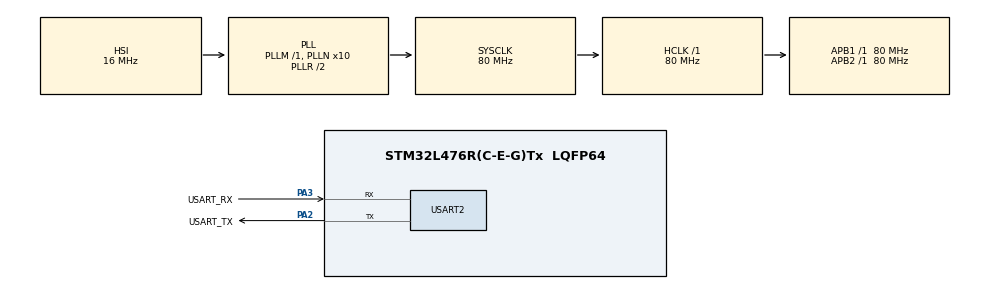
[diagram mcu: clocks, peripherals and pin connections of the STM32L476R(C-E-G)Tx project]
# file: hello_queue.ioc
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Mcu.Family=STM32L4
RCC.MSI_VALUE=4000000
RCC.PLLSourceVirtual=RCC_PLLSOURCE_HSI
PA14\ (JTCK-SWCLK).Mode=Serial_Wire
PA2.GPIO_PuPd=GPIO_NOPULL
VP_SYS_VS_tim6.Mode=TIM6
RCC.CortexFreq_Value=80000000
FREERTOS.Tasks01=sender0Task,16,128,StartSenderTask,Default,NULL,Dynamic,NULL,NULL;sender1Task,16,128,StartSenderTask,Default,NULL,Dynamic,NULL,NULL;receiver0Task,24,128,StartReceiverTask,Default,NULL,Dynamic,NULL,NULL
NVIC.TIM6_DAC_IRQn=true\:0\:0\:false\:false\:true\:false\:false\:true
PH0-OSC_IN\ (PH0).Signal=RCC_OSC_IN
PA3.GPIO_PuPd=GPIO_NOPULL
PA2.GPIO_Speed=GPIO_SPEED_FREQ_VERY_HIGH
PC15-OSC32_OUT\ (PC15).Signal=RCC_OSC32_OUT
PB3\ (JTDO-TRACESWO).GPIO_Label=SWO
PA14\ (JTCK-SWCLK).GPIO_Label=TCK
PC15-OSC32_OUT\ (PC15).Mode=LSE-External-Oscillator
PA3.GPIO_Speed=GPIO_SPEED_FREQ_VERY_HIGH
PH1-OSC_OUT\ (PH1).Signal=RCC_OSC_OUT
RCC.SYSCLKSource=RCC_SYSCLKSOURCE_PLLCLK
ProjectManager.StackSize=0x400
PB3\ (JTDO-TRACESWO).Signal=SYS_JTDO-SWO
PC14-OSC32_IN\ (PC14).Mode=LSE-External-Oscillator
VP_FREERTOS_VS_CMSIS_V2.Mode=CMSIS_V2
PA14\ (JTCK-SWCLK).Signal=SYS_JTCK-SWCLK
PA3.Mode=Asynchronous
ProjectManager.TargetToolchain=STM32CubeIDE
PA3.GPIO_Mode=GPIO_MODE_AF_PP
RCC.HCLKFreq_Value=80000000
RCC.APB2TimFreq_Value=80000000
RCC.USBFreq_Value=64000000
RCC.AHBFreq_Value=80000000
RCC.PREFETCH_ENABLE=1
RCC.HSE_VALUE=8000000
board=NUCLEO-L476RG
USART2.VirtualMode-Asynchronous=VM_ASYNC
RCC.VCOOutputFreq_Value=160000000
RCC.APB2Freq_Value=80000000
PA13\ (JTMS-SWDIO).GPIO_Label=TMS
RCC.ADCFreq_Value=64000000
Mcu.Name=STM32L476R(C-E-G)Tx
PA2.Signal=USART2_TX
PA13\ (JTMS-SWDIO).Mode=Serial_Wire
RCC.SYSCLKFreq_VALUE=80000000
Mcu.Package=LQFP64
NVIC.TimeBase=TIM6_DAC_IRQn
PC14-OSC32_IN\ (PC14).Signal=RCC_OSC32_IN
PA2.GPIO_Label=USART_TX
NVIC.TimeBaseIP=TIM6
ProjectManager.HeapSize=0x200
RCC.HSI_VALUE=16000000
NVIC.PriorityGroup=NVIC_PRIORITYGROUP_4
RCC.PLLN=10
RCC.APB1TimFreq_Value=80000000
PA2.Mode=Asynchronous
PA13\ (JTMS-SWDIO).Signal=SYS_JTMS-SWDIO
RCC.APB1Freq_Value=80000000
PA3.GPIO_Label=USART_RX
PA3.Signal=USART2_RX
PA2.GPIO_Mode=GPIO_MODE_AF_PP

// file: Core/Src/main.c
/* USER CODE BEGIN Header */
/**
  ******************************************************************************
  * @file           : main.c
  * @brief          : Main program body
  ******************************************************************************
  * @attention
  *
  * <h2><center>&copy; Copyright (c) 2021 STMicroelectronics.
  * All rights reserved.</center></h2>
  *
  * This software component is licensed by ST under BSD 3-Clause license,
  * the "License"; You may not use this file except in compliance with the
  * License. You may obtain a copy of the License at:
  *                        opensource.org/licenses/BSD-3-Clause
  *
  ******************************************************************************
  */
/* USER CODE END Header */
#include "main.h"
#include "cmsis_os.h"

/* USER CODE BEGIN Includes */
#include <stdio.h>
/* USER CODE END Includes */

/* USER CODE BEGIN PTD */
#ifdef __GNUC__
	#define PUTCHAR_PROTOTYPE int __io_putchar(int ch)
#else
	#define PUTCHAR_PROTOTYPE int fputc(int ch, FILE *f)
#endif /* __GNUC__ */
/* USER CODE END PTD */

UART_HandleTypeDef huart2;

/* Definitions for sender0Task */
osThreadId_t sender0TaskHandle;
const osThreadAttr_t sender0Task_attributes = {
  .name = "sender0Task",
  .stack_size = 128 * 4,
  .priority = (osPriority_t) osPriorityBelowNormal,
};
/* Definitions for sender1Task */
osThreadId_t sender1TaskHandle;
const osThreadAttr_t sender1Task_attributes = {
  .name = "sender1Task",
  .stack_size = 128 * 4,
  .priority = (osPriority_t) osPriorityBelowNormal,
};
/* Definitions for receiver0Task */
osThreadId_t receiver0TaskHandle;
const osThreadAttr_t receiver0Task_attributes = {
  .name = "receiver0Task",
  .stack_size = 128 * 4,
  .priority = (osPriority_t) osPriorityNormal,
};
/* USER CODE BEGIN PV */

typedef struct {
  uint8_t Buf[32];
  uint8_t Idx;
} MSGQUEUE_OBJ_t;

osMessageQueueId_t messageQueue;

/* USER CODE END PV */

void SystemClock_Config(void);
static void MX_GPIO_Init(void);
static void MX_USART2_UART_Init(void);
void StartSenderTask(void *argument);
void StartReceiverTask(void *argument);

int main(void)
{
  /* USER CODE BEGIN 1 */
	const char* sender0Tag = "Sender0";
	const char* sender1Tag = "Sender1";
	const char* sender2Tag = "Sender2";
  /* USER CODE END 1 */

  /* MCU Configuration--------------------------------------------------------*/

  /* Reset of all peripherals, Initializes the Flash interface and the Systick. */
  HAL_Init();

  /* Configure the system clock */
  SystemClock_Config();

  /* Initialize all configured peripherals */
  MX_GPIO_Init();
  MX_USART2_UART_Init();

  /* Init scheduler */
  osKernelInitialize();

  /* USER CODE BEGIN RTOS_QUEUES */
  /* add queues, ... */
  messageQueue = osMessageQueueNew(32, sizeof(MSGQUEUE_OBJ_t), NULL);
  if (messageQueue == NULL)
  {
  	printf("ERROR: messageQueue could not be created.\r\n");
  }
  /* USER CODE END RTOS_QUEUES */

  /* Create the thread(s) */

  /* creation of receiver0Task */
  receiver0TaskHandle = osThreadNew(StartReceiverTask, NULL, &receiver0Task_attributes);

  /* creation of sender1Task */
  sender1TaskHandle = osThreadNew(StartSenderTask, (void *)sender1Tag, &sender1Task_attributes);

  /* creation of sender0Task */
  sender0TaskHandle = osThreadNew(StartSenderTask, (void *)sender0Tag, &sender0Task_attributes);

  /* creation of receiver0Task */
  //receiver0TaskHandle = osThreadNew(StartReceiverTask, NULL, &receiver0Task_attributes);

  /* Start scheduler */
  osKernelStart();

  /* We should never get here as control is now taken by the scheduler */
  /* Infinite loop */
  for (;;)
  {

  }
}

void SystemClock_Config(void)
{
  RCC_OscInitTypeDef RCC_OscInitStruct = {0};
  RCC_ClkInitTypeDef RCC_ClkInitStruct = {0};
  RCC_PeriphCLKInitTypeDef PeriphClkInit = {0};

  /** Initializes the RCC Oscillators according to the specified parameters
  * in the RCC_OscInitTypeDef structure.
  */
  RCC_OscInitStruct.OscillatorType = RCC_OSCILLATORTYPE_HSI;
  RCC_OscInitStruct.HSIState = RCC_HSI_ON;
  RCC_OscInitStruct.HSICalibrationValue = RCC_HSICALIBRATION_DEFAULT;
  RCC_OscInitStruct.PLL.PLLState = RCC_PLL_ON;
  RCC_OscInitStruct.PLL.PLLSource = RCC_PLLSOURCE_HSI;
  RCC_OscInitStruct.PLL.PLLM = 1;
  RCC_OscInitStruct.PLL.PLLN = 10;
  RCC_OscInitStruct.PLL.PLLP = RCC_PLLP_DIV7;
  RCC_OscInitStruct.PLL.PLLQ = RCC_PLLQ_DIV2;
  RCC_OscInitStruct.PLL.PLLR = RCC_PLLR_DIV2;
  if (HAL_RCC_OscConfig(&RCC_OscInitStruct) != HAL_OK)
  {
    Error_Handler();
  }
  /** Initializes the CPU, AHB and APB buses clocks
  */
  RCC_ClkInitStruct.ClockType = RCC_CLOCKTYPE_HCLK|RCC_CLOCKTYPE_SYSCLK
                              |RCC_CLOCKTYPE_PCLK1|RCC_CLOCKTYPE_PCLK2;
  RCC_ClkInitStruct.SYSCLKSource = RCC_SYSCLKSOURCE_PLLCLK;
  RCC_ClkInitStruct.AHBCLKDivider = RCC_SYSCLK_DIV1;
  RCC_ClkInitStruct.APB1CLKDivider = RCC_HCLK_DIV1;
  RCC_ClkInitStruct.APB2CLKDivider = RCC_HCLK_DIV1;

  if (HAL_RCC_ClockConfig(&RCC_ClkInitStruct, FLASH_LATENCY_4) != HAL_OK)
  {
    Error_Handler();
  }
  PeriphClkInit.PeriphClockSelection = RCC_PERIPHCLK_USART2;
  PeriphClkInit.Usart2ClockSelection = RCC_USART2CLKSOURCE_PCLK1;
  if (HAL_RCCEx_PeriphCLKConfig(&PeriphClkInit) != HAL_OK)
  {
    Error_Handler();
  }
  /** Configure the main internal regulator output voltage
  */
  if (HAL_PWREx_ControlVoltageScaling(PWR_REGULATOR_VOLTAGE_SCALE1) != HAL_OK)
  {
    Error_Handler();
  }
}

static void MX_USART2_UART_Init(void)
{

  huart2.Instance = USART2;
  huart2.Init.BaudRate = 115200;
  huart2.Init.WordLength = UART_WORDLENGTH_8B;
  huart2.Init.StopBits = UART_STOPBITS_1;
  huart2.Init.Parity = UART_PARITY_NONE;
  huart2.Init.Mode = UART_MODE_TX_RX;
  huart2.Init.HwFlowCtl = UART_HWCONTROL_NONE;
  huart2.Init.OverSampling = UART_OVERSAMPLING_16;
  huart2.Init.OneBitSampling = UART_ONE_BIT_SAMPLE_DISABLE;
  huart2.AdvancedInit.AdvFeatureInit = UART_ADVFEATURE_NO_INIT;
  if (HAL_UART_Init(&huart2) != HAL_OK)
  {
    Error_Handler();
  }

}

static void MX_GPIO_Init(void)
{

  /* GPIO Ports Clock Enable */
  __HAL_RCC_GPIOC_CLK_ENABLE();
  __HAL_RCC_GPIOH_CLK_ENABLE();
  __HAL_RCC_GPIOA_CLK_ENABLE();
  __HAL_RCC_GPIOB_CLK_ENABLE();

}

/* USER CODE BEGIN 4 */
PUTCHAR_PROTOTYPE
{
	HAL_UART_Transmit(&huart2, (uint8_t *)&ch, 1, 0xFFFF);
	return ch;
}

/* USER CODE END 4 */

void StartSenderTask(void *argument)
{
  /* USER CODE BEGIN 5 */
  MSGQUEUE_OBJ_t msg;
  osStatus_t status;
  const char* senderTag = (char *)argument;

  msg.Idx = 0;
  /* Infinite loop */
  for(;;)
  {
		printf("%s\r\n", senderTag);

  	//msg.Buf[0] = 0x55U;
  	msg.Idx++;
  	//status = osMessageQueuePut(messageQueue, &msg, 0U, 0U);
  	status = osMessageQueuePut(messageQueue, &msg, 0U, 0);
  	osThreadYield();
  	if (status == osOK) {
  		printf("%s sends message: %ld.\r\n", senderTag, (int32_t)msg.Idx);
  	}
  	else
  	{
  		printf("Failed to send message.\r\n");
  	}

  	//osDelay(100);
  }
  /* USER CODE END 5 */
}

void StartReceiverTask(void *argument)
{
  /* USER CODE BEGIN StartReceiverTask */
  /* Infinite loop */
  MSGQUEUE_OBJ_t msg;
  osStatus_t status;
  for(;;)
  {
		//printf("RECEIVE\r\n");
  	status = osMessageQueueGet(messageQueue, &msg, NULL, osWaitForever);   // wait for message
  	if (status == osOK) {
  		printf("Message received: %ld.\r\n", (int32_t)msg.Idx);
  	}
  	else
  	{
  		printf("Failed to receive message.\r\n");
  	}

  	//printf("Receive\r\n");
    //osDelay(50);
  }
  /* USER CODE END StartReceiverTask */
}

 /**
  * @brief  Period elapsed callback in non blocking mode
  * @note   This function is called  when TIM6 interrupt took place, inside
  * HAL_TIM_IRQHandler(). It makes a direct call to HAL_IncTick() to increment
  * a global variable "uwTick" used as application time base.
  * @param  htim : TIM handle
  * @retval None
  */
void HAL_TIM_PeriodElapsedCallback(TIM_HandleTypeDef *htim)
{
  if (htim->Instance == TIM6) {
    HAL_IncTick();
  }
}

void Error_Handler(void)
{
  __disable_irq();
  while (1)
  {
  }
}

/************************ (C) COPYRIGHT STMicroelectronics *****END OF FILE****/
